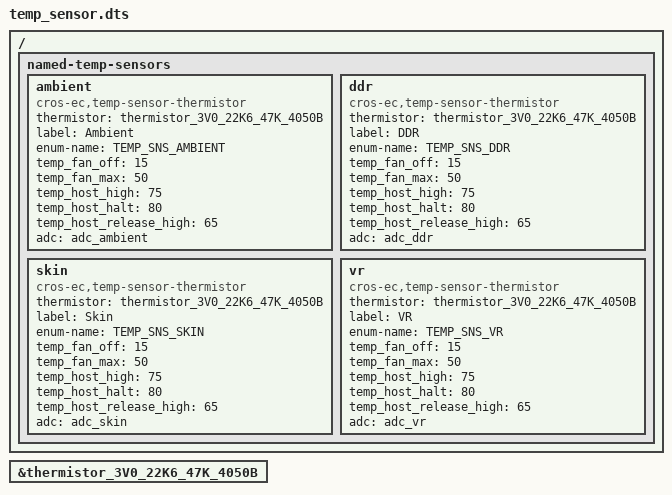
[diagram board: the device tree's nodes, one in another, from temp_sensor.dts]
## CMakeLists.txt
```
# Copyright 2022 The Chromium OS Authors. All rights reserved.
# Use of this source code is governed by a BSD-style license that can be
# found in the LICENSE file.

cmake_minimum_required(VERSION 3.13.1)

find_package(Zephyr REQUIRED HINTS "${ZEPHYR_BASE}")
project(intelrvp)

cros_ec_library_include_directories(include)
cros_ec_library_include_directories("${PLATFORM_EC}/driver/charger")
cros_ec_library_include_directories("${PLATFORM_EC}/driver/ppc")
cros_ec_library_include_directories("${PLATFORM_EC}/driver/tcpm")
cros_ec_library_include_directories("${PLATFORM_EC}/driver/usb_mux")
zephyr_library_sources("src/intel_rvp_board_id.c")

if(DEFINED CONFIG_BOARD_ADLRVP_NPCX)
  add_subdirectory(adlrvp)
  zephyr_library_sources("src/intelrvp.c")
  zephyr_library_sources_ifdef(CONFIG_PLATFORM_EC_USBC "${PLATFORM_EC}/baseboard/intelrvp/usb_pd_policy_mecc_1_0.c")
  zephyr_library_sources_ifdef(CONFIG_PLATFORM_EC_USBC "${PLATFORM_EC}/baseboard/intelrvp/chg_usb_pd_mecc_1_0.c")
  zephyr_library_sources_ifdef(CONFIG_PLATFORM_EC_USBC "${PLATFORM_EC}/baseboard/intelrvp/chg_usb_pd.c")
  zephyr_library_sources_ifdef(CONFIG_PLATFORM_EC_LED_PWM "src/intel_rvp_led.c")
endif()

if((DEFINED CONFIG_BOARD_MTLRVP_MCHP) OR (DEFINED CONFIG_BOARD_MTLRVP_NPCX))
  add_subdirectory(mtlrvp)
  zephyr_library_sources("src/intelrvp.c")
  zephyr_library_sources_ifdef(CONFIG_PLATFORM_EC_USBC "src/usb_pd_policy_mecc_1_1.c")
  zephyr_library_sources_ifdef(CONFIG_PLATFORM_EC_USBC "src/chg_usb_pd_mecc_1_1.c")
  zephyr_library_sources_ifdef(CONFIG_PLATFORM_EC_USBC "src/chg_usb_pd.c")
endif()
```

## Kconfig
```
# Copyright 2022 The Chromium OS Authors. All rights reserved.
# Use of this source code is governed by a BSD-style license that can be
# found in the LICENSE file.

config BOARD_ADLRVP_NPCX
	bool "Intel ADLRVP_NPCX board"
	depends on SOC_NPCX9M7F
	help
	  Build Intel ADLRVP_NPCX reference board. This board has Intel ADL RVP
	  SoC with NPCX9M37F EC.

config BOARD_MTLRVP_MCHP
	bool "Intel MTLRVP_MCHP board"
	depends on SOC_MEC172X_NSZ
	help
	  Build Intel MTLRVP_MCHP reference board. This board has Intel MTL RVP
	  SoC with MEC1727 EC

config BOARD_MTLRVP_NPCX
	bool "Intel MTLRVP_NPCX board"
	depends on SOC_NPCX9M3F
	help
	  Build Intel MTLRVP_NPCX reference board. This board is Intel MTL RVP
	  SOC with NPCX_NPCX9M3F

source "Kconfig.zephyr"
```

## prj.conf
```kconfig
# Copyright 2022 The ChromiumOS Authors
# Use of this source code is governed by a BSD-style license that can be
# found in the LICENSE file.


CONFIG_CROS_EC=y
CONFIG_LTO=y
CONFIG_PLATFORM_EC=y
CONFIG_PLATFORM_EC_POWER_BUTTON=y
CONFIG_PLATFORM_EC_LID_SWITCH=y
CONFIG_PLATFORM_EC_EXTPOWER_GPIO=y
CONFIG_SHIMMED_TASKS=y

# Battery
CONFIG_PLATFORM_EC_BATTERY=y
CONFIG_PLATFORM_EC_BATTERY_CUT_OFF=y
CONFIG_PLATFORM_EC_BATTERY_FUEL_GAUGE=y
CONFIG_PLATFORM_EC_BATTERY_PRESENT_GPIO=y
CONFIG_PLATFORM_EC_BATTERY_REVIVE_DISCONNECT=y
CONFIG_PLATFORM_EC_BATTERY_SMART=y
CONFIG_PLATFORM_EC_BATTERY_TYPE_NO_AUTO_DETECT=y
CONFIG_PLATFORM_EC_CHARGER_MIN_POWER_MW_FOR_POWER_ON_WITH_BATT=15000
CONFIG_PLATFORM_EC_CHARGER_MIN_POWER_MW_FOR_POWER_ON=15001

#Power Sequencing
CONFIG_PLATFORM_EC_BOARD_RESET_AFTER_POWER_ON=y

# Host command
CONFIG_PLATFORM_EC_HOSTCMD_AP_RESET=y
CONFIG_PLATFORM_EC_PORT80=y

# USB-C and PD
CONFIG_PLATFORM_EC_USB_VID=0x18d1
CONFIG_PLATFORM_EC_USB_PID=0x8086
CONFIG_PLATFORM_EC_USB_PD_REQUIRE_AP_MODE_ENTRY=y

# I2C
CONFIG_I2C=y

# eSPI
CONFIG_ESPI=y
CONFIG_PLATFORM_EC_HOST_INTERFACE_ESPI_VW_SLP_S3=y
CONFIG_PLATFORM_EC_HOST_INTERFACE_ESPI_VW_SLP_S4=y
CONFIG_PLATFORM_EC_HOST_INTERFACE_ESPI_VW_SLP_S5=y

# Keyboard
CONFIG_PLATFORM_EC_KEYBOARD=y
CONFIG_PLATFORM_EC_KEYBOARD_PROTOCOL_8042=y
CONFIG_PLATFORM_EC_KEYBOARD_COL2_INVERTED=y
CONFIG_PLATFORM_EC_KEYBOARD_PWRBTN_ASSERTS_KSI2=y
CONFIG_PLATFORM_EC_VOLUME_BUTTONS=y
CONFIG_PLATFORM_EC_CMD_BUTTON=n

# Shell Commands
CONFIG_SHELL_HELP=y
CONFIG_SHELL_HISTORY=y
CONFIG_SHELL_TAB=y
CONFIG_SHELL_TAB_AUTOCOMPLETION=y
CONFIG_KERNEL_SHELL=y

CONFIG_SYSTEM_BOOT_TIME_LOGGING=y

# TODO
# Below conf are disabled to compile successfully
# These will be enabled in upcoming CLs
CONFIG_PLATFORM_EC_BACKLIGHT_LID=n
```

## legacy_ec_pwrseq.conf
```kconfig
# Copyright 2022 The ChromiumOS Authors. All rights reserved.
# Use of this source code is governed by a BSD-style license that can be
# found in the LICENSE file.

# Legacy EC Power Sequencing Common Config
CONFIG_PLATFORM_EC_POWERSEQ=y
CONFIG_PLATFORM_EC_POWERSEQ_HOST_SLEEP=y
CONFIG_PLATFORM_EC_POWERSEQ_INTEL=y
CONFIG_PLATFORM_EC_POWERSEQ_RSMRST_DELAY=y
CONFIG_PLATFORM_EC_POWERSEQ_S0IX=y
CONFIG_PLATFORM_EC_POWERSEQ_S4=y
CONFIG_PLATFORM_EC_THROTTLE_AP=y
```

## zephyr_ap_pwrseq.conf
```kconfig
# Copyright 2022 The ChromiumOS Authors. All rights reserved.
# Use of this source code is governed by a BSD-style license that can be
# found in the LICENSE file.

# Zephyr Inbuilt AP Power Sequencing Config
CONFIG_AP_PWRSEQ=y
CONFIG_X86_NON_DSX_PWRSEQ_CONSOLE=y
CONFIG_AP_PWRSEQ_S0IX=y
```

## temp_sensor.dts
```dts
/* Copyright 2022 The Chromium OS Authors. All rights reserved.
 * Use of this source code is governed by a BSD-style license that can be
 * found in the LICENSE file.
 */

#include <cros/thermistor/thermistor.dtsi>

/ {
	named-temp-sensors {
		ambient {
			compatible = "cros-ec,temp-sensor-thermistor";
			thermistor = <&thermistor_3V0_22K6_47K_4050B>;
			label = "Ambient";
			enum-name = "TEMP_SNS_AMBIENT";
			temp_fan_off = <15>;
			temp_fan_max = <50>;
			temp_host_high = <75>;
			temp_host_halt = <80>;
			temp_host_release_high = <65>;
			adc = <&adc_ambient>;
		};

		/*
		 * TDB: battery temp read api is not using thermistor and
		 * zephyr shim layer doesn't support to configure custom read
		 * function.
		 *
		 * battery {
		 *	compatible = "cros-ec,temp-sensor-thermistor";
		 *	thermistor = <&thermistor_3V0_22K6_47K_4050B>;
		 *	label = "Battery";
		 *	enum-name = "TEMP_SNS_BATTERY";
		 *	temp_fan_off = <15>;
		 *	temp_fan_max = <50>;
		 *	temp_host_high = <75>;
		 *	temp_host_halt = <80>;
		 *	temp_host_release_high = <65>;
		 *	adc = <&adc_battery>;
		 * };
		 */

		ddr {
			compatible = "cros-ec,temp-sensor-thermistor";
			thermistor = <&thermistor_3V0_22K6_47K_4050B>;
			label = "DDR";
			enum-name = "TEMP_SNS_DDR";
			temp_fan_off = <15>;
			temp_fan_max = <50>;
			temp_host_high = <75>;
			temp_host_halt = <80>;
			temp_host_release_high = <65>;
			adc = <&adc_ddr>;
		};
		skin {
			compatible = "cros-ec,temp-sensor-thermistor";
			thermistor = <&thermistor_3V0_22K6_47K_4050B>;
			label = "Skin";
			enum-name = "TEMP_SNS_SKIN";
			temp_fan_off = <15>;
			temp_fan_max = <50>;
			temp_host_high = <75>;
			temp_host_halt = <80>;
			temp_host_release_high = <65>;
			adc = <&adc_skin>;
		};
		vr {
			compatible = "cros-ec,temp-sensor-thermistor";
			thermistor = <&thermistor_3V0_22K6_47K_4050B>;
			label = "VR";
			enum-name = "TEMP_SNS_VR";
			temp_fan_off = <15>;
			temp_fan_max = <50>;
			temp_host_high = <75>;
			temp_host_halt = <80>;
			temp_host_release_high = <65>;
			adc = <&adc_vr>;
		};
	};
};

&thermistor_3V0_22K6_47K_4050B {
	status = "okay";
};
```

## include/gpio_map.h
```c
/* Copyright 2022 The Chromium OS Authors. All rights reserved.
 * Use of this source code is governed by a BSD-style license that can be
 * found in the LICENSE file.
 */

#ifndef __ZEPHYR_GPIO_MAP_H
#define __ZEPHYR_GPIO_MAP_H

#define GPIO_TEMP_SENSOR_POWER GPIO_EN_PP3300_A

#endif /* __ZEPHYR_GPIO_MAP_H */
```

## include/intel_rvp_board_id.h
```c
/* Copyright 2022 The ChromiumOS Authors. All rights reserved.
 * Use of this source code is governed by a BSD-style license that can be
 * found in the LICENSE file.
 */

#ifndef __INTEL_RVP_BOARD_ID_H
#define __INTEL_RVP_BOARD_ID_H

#include <zephyr/drivers/gpio.h>

extern const struct gpio_dt_spec bom_id_config[];

extern const struct gpio_dt_spec fab_id_config[];

extern const struct gpio_dt_spec board_id_config[];

#endif /* __INTEL_RVP_BOARD_ID_H */
```

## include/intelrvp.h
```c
/* Copyright 2022 The Chromium OS Authors. All rights reserved.
 * Use of this source code is governed by a BSD-style license that can be
 * found in the LICENSE file.
 */
#ifndef __INTELRVP_BOARD_H
#define __INTELRVP_BOARD_H

#include "compiler.h"
#include "gpio_signal.h"
#include "stdbool.h"

/* RVP ID read retry count */
#define RVP_VERSION_READ_RETRY_CNT 2

#define DC_JACK_MAX_VOLTAGE_MV 19000

FORWARD_DECLARE_ENUM(tcpc_rp_value);

struct tcpc_aic_gpio_config_t {
	/* TCPC interrupt */
	enum gpio_signal tcpc_alert;
	/* PPC interrupt */
	enum gpio_signal ppc_alert;
	/* PPC interrupt handler */
	void (*ppc_intr_handler)(int port);
};
extern const struct tcpc_aic_gpio_config_t tcpc_aic_gpios[];

void board_charging_enable(int port, int enable);
void board_vbus_enable(int port, int enable);
void board_set_vbus_source_current_limit(int port, enum tcpc_rp_value rp);
void board_dc_jack_interrupt(enum gpio_signal signal);
void tcpc_alert_event(enum gpio_signal signal);
bool is_typec_port(int port);
bool is_intel_ccd_attached(void);
#endif /* __INTELRVP_BOARD_H */
```

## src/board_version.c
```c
/* Copyright 2022 The Chromium OS Authors. All rights reserved.
 * Use of this source code is governed by a BSD-style license that can be
 * found in the LICENSE file.
 */

#include "common.h"
#include "console.h"
#include "intelrvp.h"
#include "intel_rvp_board_id.h"

#define CPRINTF(format, args...) cprintf(CC_COMMAND, format, ## args)
#define CPRINTS(format, args...) cprints(CC_COMMAND, format, ## args)

/*
 * Returns board information (board id[7:0] and Fab id[15:8]) on success
 * -1 on error.
 */
__override int board_get_version(void)
{
	/* Cache the board ID */
	static int rvp_board_id;

	int i;
	int rv = EC_ERROR_UNKNOWN;

	int fab_id, board_id, bom_id;

	/* Board ID is already read */
	if (rvp_board_id)
		return rvp_board_id;

	/*
	 * IOExpander that has Board ID information is on DSW-VAL rail on
	 * ADL RVP. On cold boot cycles, DSW-VAL rail is taking time to settle.
	 * This loop retries to ensure rail is settled and read is successful
	 */
	for (i = 0; i < RVP_VERSION_READ_RETRY_CNT; i++) {

		rv  = gpio_pin_get_dt(&bom_id_config[0]);

		if (rv >= 0)
			break;

		k_msleep(1);
	}

	/* retrun -1 if failed to read board id */
	if (rv < 0)
		return -1;

	/*
	 * BOM ID [2]   : IOEX[0]
	 * BOM ID [1:0] : IOEX[15:14]
	 */
	bom_id  = gpio_pin_get_dt(&bom_id_config[0]) << 2;
	bom_id |= gpio_pin_get_dt(&bom_id_config[1]) << 1;
	bom_id |= gpio_pin_get_dt(&bom_id_config[2]);

	/*
	 * FAB ID [1:0] : IOEX[2:1] + 1
	 */
	fab_id  = gpio_pin_get_dt(&fab_id_config[0]) << 1;
	fab_id |= gpio_pin_get_dt(&fab_id_config[1]);
	fab_id += 1;

	/*
	 * BOARD ID[5:0] : IOEX[13:8]
	 */
	board_id  = gpio_pin_get_dt(&board_id_config[0]) << 5;
	board_id |= gpio_pin_get_dt(&board_id_config[1]) << 4;
	board_id |= gpio_pin_get_dt(&board_id_config[2]) << 3;
	board_id |= gpio_pin_get_dt(&board_id_config[3]) << 2;
	board_id |= gpio_pin_get_dt(&board_id_config[4]) << 1;
	board_id |= gpio_pin_get_dt(&board_id_config[5]);

	CPRINTF("BID:0x%x, FID:0x%x, BOM:0x%x", board_id, fab_id, bom_id);

	rvp_board_id = board_id | (fab_id << 8);
	return rvp_board_id;
}
```

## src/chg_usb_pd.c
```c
/* Copyright 2022 The ChromiumOS Authors.
 * Use of this source code is governed by a BSD-style license that can be
 * found in the LICENSE file.
 */

/* Common USB PD charge configuration */

#include "charge_manager.h"
#include "charge_state_v2.h"
#include "gpio.h"
#include "hooks.h"
#include "intelrvp.h"
#include "tcpm/tcpci.h"

#define CPRINTF(format, args...) cprintf(CC_USBPD, format, ##args)
LOG_MODULE_DECLARE(usbpd);
#define CPRINTS(format, args...) cprints(CC_USBPD, format, ##args)

bool is_typec_port(int port)
{
#if CONFIG_DEDICATED_CHARGE_PORT_COUNT > 0
	return !(port == DEDICATED_CHARGE_PORT || port == CHARGE_PORT_NONE);
#else
	return !(port == CHARGE_PORT_NONE);
#endif /* CONFIG_DEDICATED_CHARGE_PORT_COUNT > 0 */
}

static inline int board_dc_jack_present(void)
{
#if CONFIG_DEDICATED_CHARGE_PORT_COUNT > 0
	return gpio_get_level(GPIO_DC_JACK_PRESENT);
#else
	return 0;
#endif /* CONFIG_DEDICATED_CHARGE_PORT_COUNT > 0 */
}

static void board_dc_jack_handle(void)
{
#if CONFIG_DEDICATED_CHARGE_PORT_COUNT > 0
	struct charge_port_info charge_dc_jack;

	/* System is booted from DC Jack */
	if (board_dc_jack_present()) {
		charge_dc_jack.current =
			(PD_MAX_POWER_MW * 1000) / DC_JACK_MAX_VOLTAGE_MV;
		charge_dc_jack.voltage = DC_JACK_MAX_VOLTAGE_MV;
	} else {
		charge_dc_jack.current = 0;
		charge_dc_jack.voltage = USB_CHARGER_VOLTAGE_MV;
	}

	charge_manager_update_charge(CHARGE_SUPPLIER_DEDICATED,
				     DEDICATED_CHARGE_PORT, &charge_dc_jack);
#endif /* CONFIG_DEDICATED_CHARGE_PORT_COUNT > 0 */
}

void board_dc_jack_interrupt(enum gpio_signal signal)
{
	board_dc_jack_handle();
}

static void board_charge_init(void)
{
	int port, supplier;
	struct charge_port_info charge_init = {
		.current = 0,
		.voltage = USB_CHARGER_VOLTAGE_MV,
	};

	/* Initialize all charge suppliers to seed the charge manager */
	for (port = 0; port < CHARGE_PORT_COUNT; port++) {
		for (supplier = 0; supplier < CHARGE_SUPPLIER_COUNT;
		     supplier++) {
			charge_manager_update_charge(supplier, port,
						     &charge_init);
		}
	}

	board_dc_jack_handle();
}
DECLARE_HOOK(HOOK_INIT, board_charge_init, HOOK_PRIO_DEFAULT);

int board_set_active_charge_port(int port)
{
	int i;
	/* charge port is a realy physical port */
	int is_real_port = (port >= 0 && port < CHARGE_PORT_COUNT);
	/* check if we are source vbus on that port */
	int source = board_vbus_source_enabled(port);

	if (is_real_port && source) {
		CPRINTS("Skip enable p%d", port);
		return EC_ERROR_INVAL;
	}

#if CONFIG_DEDICATED_CHARGE_PORT_COUNT > 0
	/*
	 * Do not enable Type-C port if the DC Jack is present.
	 * When the Type-C is active port, hardware circuit will
	 * block DC jack from enabling +VADP_OUT.
	 */
	if (port != DEDICATED_CHARGE_PORT && board_dc_jack_present()) {
		CPRINTS("DC Jack present, Skip enable p%d", port);
		return EC_ERROR_INVAL;
	}
#endif /* CONFIG_DEDICATED_CHARGE_PORT_COUNT */

	/* Make sure non-charging ports are disabled */
	for (i = 0; i < CONFIG_USB_PD_PORT_MAX_COUNT; i++) {
		if (i != port) {
			board_charging_enable(i, 0);
		}
	}

	/* Enable charging port */
	if (is_typec_port(port)) {
		board_charging_enable(port, 1);
	}

	CPRINTS("New chg p%d", port);

	return EC_SUCCESS;
}

void board_set_charge_limit(int port, int supplier, int charge_ma, int max_ma,
			    int charge_mv)
{
	charge_set_input_current_limit(
		MAX(charge_ma, CONFIG_CHARGER_INPUT_CURRENT), charge_mv);
}
```

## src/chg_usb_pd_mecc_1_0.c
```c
/* Copyright 2022 The Chromium OS Authors. All rights reserved.
 * Use of this source code is governed by a BSD-style license that can be
 * found in the LICENSE file.
 */

/* Intel-RVP family-specific configuration */

#include "charge_manager.h"
#include "charge_state_v2.h"
#include "console.h"
#include "driver/ppc/sn5s330.h"
#include "hooks.h"
#include "tcpm/tcpci.h"
#include "system.h"
#include "usbc_ppc.h"
#include "intelrvp.h"

#define CPRINTF(format, args...) cprintf(CC_USBPD, format, ## args)
#define CPRINTS(format, args...) cprints(CC_USBPD, format, ## args)

/* Reset PD MCU */
void board_reset_pd_mcu(void)
{
	/* Add code if TCPC chips need a reset */
}

static void baseboard_tcpc_init(void)
{
	int i;

	/* Only reset TCPC if not sysjump */
	if (!system_jumped_late())
		board_reset_pd_mcu();

	for (i = 0; i < CONFIG_USB_PD_PORT_MAX_COUNT; i++) {
		/* Enable PPC interrupts. */
		if (tcpc_aic_gpios[i].ppc_intr_handler)
			gpio_enable_interrupt(tcpc_aic_gpios[i].ppc_alert);

		/* Enable TCPC interrupts. */
		if (tcpc_config[i].bus_type != EC_BUS_TYPE_EMBEDDED)
			gpio_enable_interrupt(tcpc_aic_gpios[i].tcpc_alert);
	}
}
DECLARE_HOOK(HOOK_INIT, baseboard_tcpc_init, HOOK_PRIO_INIT_CHIPSET);

void tcpc_alert_event(enum gpio_signal signal)
{
	int i;

	for (i = 0; i < CONFIG_USB_PD_PORT_MAX_COUNT; i++) {
		/* No alerts for embdeded TCPC */
		if (tcpc_config[i].bus_type == EC_BUS_TYPE_EMBEDDED)
			continue;

		if (signal == tcpc_aic_gpios[i].tcpc_alert) {
			schedule_deferred_pd_interrupt(i);
			break;
		}
	}
}

uint16_t tcpc_get_alert_status(void)
{
	uint16_t status = 0;
	int i;

	/* Check which port has the ALERT line set */
	for (i = 0; i < CONFIG_USB_PD_PORT_MAX_COUNT; i++) {
		/* No alerts for embdeded TCPC */
		if (tcpc_config[i].bus_type == EC_BUS_TYPE_EMBEDDED)
			continue;

		if (!gpio_get_level(tcpc_aic_gpios[i].tcpc_alert))
			status |= PD_STATUS_TCPC_ALERT_0 << i;
	}

	return status;
}

int ppc_get_alert_status(int port)
{
	if (!tcpc_aic_gpios[port].ppc_intr_handler)
		return 0;

	return !gpio_get_level(tcpc_aic_gpios[port].ppc_alert);
}

/* PPC support routines */
void ppc_interrupt(enum gpio_signal signal)
{
	int i;

	for (i = 0; i < CONFIG_USB_PD_PORT_MAX_COUNT; i++) {
		if (tcpc_aic_gpios[i].ppc_intr_handler &&
			signal == tcpc_aic_gpios[i].ppc_alert) {
			tcpc_aic_gpios[i].ppc_intr_handler(i);
			break;
		}
	}
}

void board_charging_enable(int port, int enable)
{
	if (ppc_vbus_sink_enable(port, enable))
		CPRINTS("C%d: sink path %s failed",
				port, enable ? "en" : "dis");
}
```

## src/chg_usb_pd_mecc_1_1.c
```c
/* Copyright 2022 The ChromiumOS Authors.
 * Use of this source code is governed by a BSD-style license that can be
 * found in the LICENSE file.
 */

/* Intel-RVP family-specific configuration */

#include "console.h"
#include "gpio/gpio_int.h"
#include "hooks.h"
#include "include/gpio.h"
#include "intelrvp.h"
#include "ioexpander.h"
#include "system.h"
#include "tcpm/tcpci.h"
#include "usbc_ppc.h"

#define CPRINTF(format, args...) cprintf(CC_USBPD, format, ##args)
LOG_MODULE_DECLARE(usbpd);
#define CPRINTS(format, args...) cprints(CC_USBPD, format, ##args)

void tcpc_alert_event(enum gpio_signal signal)
{
	int i;

	for (i = 0; i < CONFIG_USB_PD_PORT_MAX_COUNT; i++) {
		/* No alerts for embedded TCPC */
		if (tcpc_config[i].bus_type == EC_BUS_TYPE_EMBEDDED) {
			continue;
		}

		if (signal == tcpc_aic_gpios[i].tcpc_alert) {
			schedule_deferred_pd_interrupt(i);
			break;
		}
	}
}

uint16_t tcpc_get_alert_status(void)
{
	uint16_t status = 0;
	int i;

	/* Check which port has the ALERT line set */
	for (i = 0; i < CONFIG_USB_PD_PORT_MAX_COUNT; i++) {
		/* No alerts for embdeded TCPC */
		if (tcpc_config[i].bus_type == EC_BUS_TYPE_EMBEDDED) {
			continue;
		}

		if (!gpio_get_level(tcpc_aic_gpios[i].tcpc_alert)) {
			status |= PD_STATUS_TCPC_ALERT_0 << i;
		}
	}

	return status;
}

int ppc_get_alert_status(int port)
{
	return tcpc_aic_gpios[port].ppc_intr_handler &&
	       !gpio_get_level(tcpc_aic_gpios[port].ppc_alert);
}

/* PPC support routines */
void ppc_interrupt(enum gpio_signal signal)
{
	int i;

	for (i = 0; i < CONFIG_USB_PD_PORT_MAX_COUNT; i++) {
		if (tcpc_aic_gpios[i].ppc_intr_handler &&
		    signal == tcpc_aic_gpios[i].ppc_alert) {
			tcpc_aic_gpios[i].ppc_intr_handler(i);
			break;
		}
	}
}

void board_charging_enable(int port, int enable)
{
	int rv;

	if (tcpc_aic_gpios[port].ppc_intr_handler) {
		rv = ppc_vbus_sink_enable(port, enable);
	} else {
		rv = tcpc_config[port].drv->set_snk_ctrl(port, enable);
	}

	if (rv) {
		CPRINTS("C%d: sink path %s failed", port,
			enable ? "en" : "dis");
	}
}
```

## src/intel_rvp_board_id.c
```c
/* Copyright 2022 The ChromiumOS Authors. All rights reserved.
 * Use of this source code is governed by a BSD-style license that can be
 * found in the LICENSE file.
 */

#include <zephyr/devicetree.h>
#include "intel_rvp_board_id.h"

#define DT_DRV_COMPAT intel_rvp_board_id

BUILD_ASSERT(DT_NUM_INST_STATUS_OKAY(DT_DRV_COMPAT) <= 1,
	     "Unsupported RVP Board ID instance");

#define RVP_ID_GPIO_DT_SPEC_GET(idx, node_id, prop) \
	GPIO_DT_SPEC_GET_BY_IDX(node_id, prop, idx),

#define RVP_ID_CONFIG_LIST(node_id, prop)                                \
	LISTIFY(DT_PROP_LEN(node_id, prop), RVP_ID_GPIO_DT_SPEC_GET, (), \
		node_id, prop)

#if DT_HAS_COMPAT_STATUS_OKAY(DT_DRV_COMPAT)
const struct gpio_dt_spec bom_id_config[] = { RVP_ID_CONFIG_LIST(DT_DRV_INST(0),
								 bom_gpios) };

const struct gpio_dt_spec fab_id_config[] = { RVP_ID_CONFIG_LIST(DT_DRV_INST(0),
								 fab_gpios) };

const struct gpio_dt_spec board_id_config[] = { RVP_ID_CONFIG_LIST(
	DT_DRV_INST(0), board_gpios) };
#endif /* #if DT_HAS_COMPAT_STATUS_OKAY */
```

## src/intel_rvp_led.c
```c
/* Copyright 2022 The ChromiumOS Authors. All rights reserved.
 * Use of this source code is governed by a BSD-style license that can be
 * found in the LICENSE file.
 */

#include "battery.h"
#include "charge_manager.h"
#include "charge_state.h"
#include "chipset.h"
#include "common.h"
#include "console.h"
#include "ec_commands.h"
#include "extpower.h"
#include "hooks.h"
#include "led_common.h"
#include "led_pwm.h"
#include "pwm.h"
#include "timer.h"
#include "util.h"

/* Battery percentage thresholds to blink at different rates. */
#define LOW_BATTERY_PERCENTAGE 10
#define NORMAL_BATTERY_PERCENTAGE 90

#define LED_OFF -1

#define LED_PULSE_TICK (125 * MSEC)

#define LED_FAST_PULSE_PERIOD (250 / 125) /* 250 ms */
#define LED_SLOW_PULSE_PERIOD ((2 * MSEC) / 125) /* 2 sec  */

struct led_pulse_data {
	bool led_is_pulsing;
	uint8_t led_pulse_period;
	uint8_t led_tick_count;
};

static struct led_pulse_data rvp_led[CONFIG_LED_PWM_COUNT];

static void pulse_led_deferred(void);
DECLARE_DEFERRED(pulse_led_deferred);

static void pulse_led_deferred(void)
{
	int i = 0;
	bool call_deferred = false;

	for (i = 0; i < CONFIG_LED_PWM_COUNT; i++) {
		if (!rvp_led[i].led_is_pulsing) {
			rvp_led[i].led_tick_count = 0;
			continue;
		}

		/*
		 * LED will be in ON state first half of the pulse period
		 * and in OFF state in second half of the pulse period.
		 */
		if (rvp_led[i].led_tick_count <
		    (rvp_led[i].led_pulse_period >> 1))
			set_pwm_led_color(i, EC_LED_COLOR_GREEN);
		else
			set_pwm_led_color(i, LED_OFF);

		rvp_led[i].led_tick_count = (rvp_led[i].led_tick_count + 1) %
					    rvp_led[i].led_pulse_period;
		call_deferred = true;
	}

	if (call_deferred)
		hook_call_deferred(&pulse_led_deferred_data, LED_PULSE_TICK);
}

static void pulse_leds(enum pwm_led_id id, int period)
{
	rvp_led[id].led_pulse_period = period;
	rvp_led[id].led_is_pulsing = true;

	pulse_led_deferred();
}

static void update_charger_led(enum pwm_led_id id)
{
	enum charge_state chg_st = charge_get_state();

	/*
	 * The colors listed below are the default, but can be overridden.
	 *
	 * Fast Flash = Charging error
	 * Slow Flash = Discharging
	 * LED on     = Charging
	 * LED off    = No Charger connected
	 */
	if (chg_st == PWR_STATE_CHARGE ||
	    chg_st == PWR_STATE_CHARGE_NEAR_FULL) {
		/* Charging: LED ON */
		rvp_led[id].led_is_pulsing = false;
		set_pwm_led_color(id, EC_LED_COLOR_GREEN);
	} else if (chg_st == PWR_STATE_DISCHARGE ||
		   chg_st == PWR_STATE_DISCHARGE_FULL) {
		if (extpower_is_present()) {
			/* Discharging:
			 * Flash slower (2 second period, 100% duty cycle)
			 */
			pulse_leds(id, LED_SLOW_PULSE_PERIOD);
		} else {
			/* No Charger connected: LED OFF */
			rvp_led[id].led_is_pulsing = false;
			set_pwm_led_color(id, LED_OFF);
		}
	} else if (chg_st == PWR_STATE_ERROR) {
		/* Charging error:
		 * Flash faster (250 ms period, 100% duty cycle)
		 */
		pulse_leds(id, LED_FAST_PULSE_PERIOD);
	} else {
		/* LED OFF */
		rvp_led[id].led_is_pulsing = false;
		set_pwm_led_color(id, LED_OFF);
	}
}

static void update_battery_led(enum pwm_led_id id)
{
	/*
	 * Fast Flash = Low Battery
	 * Slow Flash = Normal Battery
	 * LED on     = Full Battery
	 * LED off    = No Battery
	 */
	if (battery_is_present() == BP_YES) {
		int batt_percentage = charge_get_percent();

		if (batt_percentage < LOW_BATTERY_PERCENTAGE) {
			/* Low Battery:
			 * Flash faster (250 ms period, 100% duty cycle)
			 */
			pulse_leds(id, LED_FAST_PULSE_PERIOD);
		} else if (batt_percentage < NORMAL_BATTERY_PERCENTAGE) {
			/* Normal Battery:
			 * Flash slower (2 second period, 100% duty cycle)
			 */
			pulse_leds(id, LED_SLOW_PULSE_PERIOD);
		} else {
			/* Full Battery: LED ON */
			rvp_led[id].led_is_pulsing = false;
			set_pwm_led_color(id, EC_LED_COLOR_GREEN);
		}
	} else {
		/* No Battery: LED OFF */
		rvp_led[id].led_is_pulsing = false;
		set_pwm_led_color(id, LED_OFF);
	}
}

static void init_rvp_leds_off(void)
{
	/* Turn off LEDs such that they are in a known state with zero duty. */
	set_pwm_led_color(PWM_LED0, LED_OFF);
	set_pwm_led_color(PWM_LED1, LED_OFF);
}
DECLARE_HOOK(HOOK_INIT, init_rvp_leds_off, HOOK_PRIO_POST_PWM);

static void update_led(void)
{
	update_battery_led(PWM_LED0);
	update_charger_led(PWM_LED1);
}
DECLARE_HOOK(HOOK_SECOND, update_led, HOOK_PRIO_DEFAULT);
```

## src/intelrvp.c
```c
/* Copyright 2022 The ChromiumOS Authors. All rights reserved.
 * Use of this source code is governed by a BSD-style license that can be
 * found in the LICENSE file.
 */

/* TODO: b/218904113: Convert to using Zephyr GPIOs */
#include "gpio.h"
#include "hooks.h"

static void board_init(void)
{
	/* Enable SOC SPI */
	gpio_pin_set_dt(GPIO_DT_FROM_NODELABEL(ec_spi_oe_mecc), 1);
}
DECLARE_HOOK(HOOK_INIT, board_init, HOOK_PRIO_LAST);

__override void intel_x86_sys_reset_delay(void)
{
	/*
	 * From MAX6818 Data sheet, Range of 'Debounce Duaration' is
	 * Minimum - 20 ms, Typical - 40 ms, Maximum - 80 ms.
	 * See b/153128296.
	 */
	udelay(60 * MSEC);
}
```

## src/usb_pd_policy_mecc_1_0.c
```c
/* Copyright 2022 The Chromium OS Authors. All rights reserved.
 * Use of this source code is governed by a BSD-style license that can be
 * found in the LICENSE file.
 */

#include "charge_manager.h"
#include "console.h"
#include "gpio.h"
#include "intelrvp.h"
#include "system.h"
#include "usb_mux.h"
#include "usb_pd.h"
#include "usbc_ppc.h"

#define CPRINTF(format, args...) cprintf(CC_USBPD, format, ## args)
#define CPRINTS(format, args...) cprints(CC_USBPD, format, ## args)

int pd_set_power_supply_ready(int port)
{
	int rv;

	/* Disable charging. */
	rv = ppc_vbus_sink_enable(port, 0);
	if (rv)
		return rv;

	pd_set_vbus_discharge(port, 0);

	/* Provide Vbus. */
	rv = ppc_vbus_source_enable(port, 1);
	if (rv)
		return rv;

	/* Notify host of power info change. */
	pd_send_host_event(PD_EVENT_POWER_CHANGE);

	return EC_SUCCESS;
}

void pd_power_supply_reset(int port)
{
	int prev_en;

	prev_en = board_vbus_source_enabled(port);

	/* Disable VBUS. */
	ppc_vbus_source_enable(port, 0);

	/* Enable discharge if we were previously sourcing 5V */
	if (prev_en)
		pd_set_vbus_discharge(port, 1);

	/* Notify host of power info change. */
	pd_send_host_event(PD_EVENT_POWER_CHANGE);
}

int pd_check_vconn_swap(int port)
{
	/* Only allow vconn swap if PP3300 rail is enabled */
	return gpio_get_level(GPIO_EN_PP3300_A);
}

int pd_snk_is_vbus_provided(int port)
{
	return ppc_is_vbus_present(port);
}

int board_vbus_source_enabled(int port)
{
	if (is_typec_port(port))
		return ppc_is_sourcing_vbus(port);
	return 0;
}
```

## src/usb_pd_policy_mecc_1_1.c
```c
/* Copyright 2022 The ChromiumOS Authors.
 * Use of this source code is governed by a BSD-style license that can be
 * found in the LICENSE file.
 */

#include "console.h"
#include "gpio.h"
#include "intelrvp.h"
#include "usb_mux.h"
#include "usbc_ppc.h"

#define CPRINTF(format, args...) cprintf(CC_USBPD, format, ##args)
LOG_MODULE_DECLARE(usbpd);
#define CPRINTS(format, args...) cprints(CC_USBPD, format, ##args)

static inline void board_pd_set_vbus_discharge(int port, bool enable)
{
	if (tcpc_aic_gpios[port].ppc_intr_handler) {
		ppc_discharge_vbus(port, enable);
	} else {
		tcpc_discharge_vbus(port, enable);
	}
}

int pd_set_power_supply_ready(int port)
{
	int rv;

	/* Disable charging. */
	if (tcpc_aic_gpios[port].ppc_intr_handler) {
		rv = ppc_vbus_sink_enable(port, 0);
	} else {
		rv = tcpc_config[port].drv->set_snk_ctrl(port, 0);
	}

	if (rv) {
		return rv;
	}

	board_pd_set_vbus_discharge(port, false);

	/* Provide Vbus. */
	if (tcpc_aic_gpios[port].ppc_intr_handler) {
		rv = ppc_vbus_source_enable(port, 1);
	} else {
		tcpc_config[port].drv->set_src_ctrl(port, 1);
	}

	if (rv) {
		return rv;
	}

	/* Notify host of power info change. */
	pd_send_host_event(PD_EVENT_POWER_CHANGE);

	return EC_SUCCESS;
}

void pd_power_supply_reset(int port)
{
	int prev_en;

	prev_en = board_vbus_source_enabled(port);

	/* Disable VBUS. */
	if (tcpc_aic_gpios[port].ppc_intr_handler) {
		ppc_vbus_source_enable(port, 0);
	} else {
		tcpc_config[port].drv->set_src_ctrl(port, 0);
	}

	/* Enable discharge if we were previously sourcing 5V */
	if (prev_en) {
		board_pd_set_vbus_discharge(port, true);
	}

	/* Notify host of power info change. */
	pd_send_host_event(PD_EVENT_POWER_CHANGE);
}

int pd_check_vconn_swap(int port)
{
	/* Only allow vconn swap if PP3300 rail is enabled */
	return gpio_get_level(GPIO_EN_PP3300_A);
}

int pd_snk_is_vbus_provided(int port)
{
	if (tcpc_aic_gpios[port].ppc_intr_handler) {
		return ppc_is_vbus_present(port);
	} else {
		return tcpc_config[port].drv->check_vbus_level(port,
							       VBUS_PRESENT);
	}
}

int board_vbus_source_enabled(int port)
{
	if (is_typec_port(port)) {
		if (tcpc_aic_gpios[port].ppc_intr_handler) {
			return ppc_is_sourcing_vbus(port);
		} else {
			return tcpc_config[port].drv->get_src_ctrl(port);
		}
	}
	return 0;
}
```
